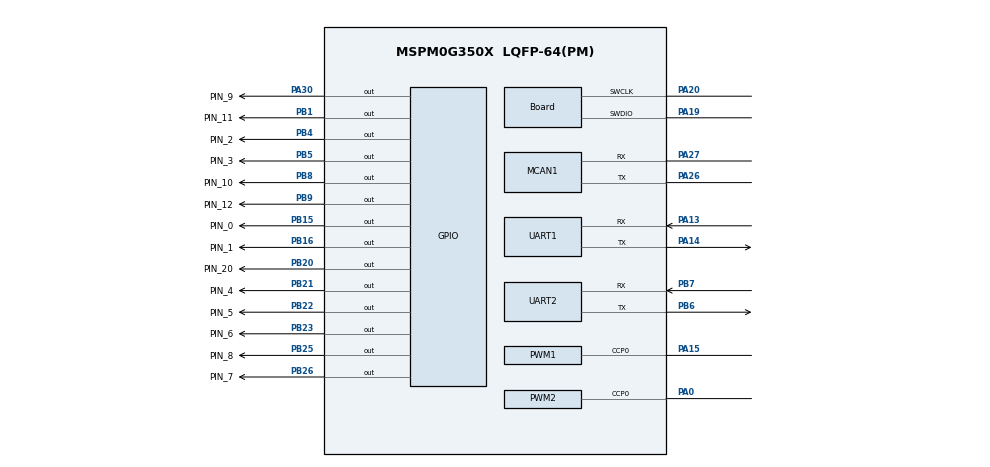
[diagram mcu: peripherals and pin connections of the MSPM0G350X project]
/**
 * @cliArgs --device "MSPM0G350X" --package "LQFP-64(PM)" --part "Default" --product "mspm0_sdk@2.00.01.00"
 * @versions {"tool":"1.20.0+3587"}
 */

/**
 * Import the modules used in this configuration.
 */
const GPIO   = scripting.addModule("/ti/driverlib/GPIO", {}, false);
const GPIO1  = GPIO.addInstance();
const GPIO2  = GPIO.addInstance();
const GPIO3  = GPIO.addInstance();
const GPIO4  = GPIO.addInstance();
const GPIO5  = GPIO.addInstance();
const GPIO6  = GPIO.addInstance();
const GPIO7  = GPIO.addInstance();
const GPIO8  = GPIO.addInstance();
const GPIO9  = GPIO.addInstance();
const GPIO10 = GPIO.addInstance();
const GPIO11 = GPIO.addInstance();
const GPIO12 = GPIO.addInstance();
const GPIO13 = GPIO.addInstance();
const GPIO14 = GPIO.addInstance();
const MCAN   = scripting.addModule("/ti/driverlib/MCAN", {}, false);
const MCAN1  = MCAN.addInstance();
const PWM    = scripting.addModule("/ti/driverlib/PWM", {}, false);
const PWM1   = PWM.addInstance();
const PWM2   = PWM.addInstance();
const SYSCTL = scripting.addModule("/ti/driverlib/SYSCTL");
const TIMER  = scripting.addModule("/ti/driverlib/TIMER", {}, false);
const TIMER1 = TIMER.addInstance();
const TIMER2 = TIMER.addInstance();
const TIMER3 = TIMER.addInstance();
const UART   = scripting.addModule("/ti/driverlib/UART", {}, false);
const UART1  = UART.addInstance();
const UART2  = UART.addInstance();
const WWDT   = scripting.addModule("/ti/driverlib/WWDT", {}, false);
const WWDT1  = WWDT.addInstance();

/**
 * Write custom configuration values to the imported modules.
 */
const divider5       = system.clockTree["PLL_CLK1_DIV"];
divider5.divideValue = 8;

const divider9       = system.clockTree["UDIV"];
divider9.divideValue = 2;

const multiplier2         = system.clockTree["PLL_QDIV"];
multiplier2.multiplyValue = 5;

const mux2       = system.clockTree["CANCLKMUX"];
mux2.inputSelect = "CANCLKMUX_PLLCLK1_OUT";

const mux8       = system.clockTree["HSCLKMUX"];
mux8.inputSelect = "HSCLKMUX_SYSPLL0";

const pinFunction4     = system.clockTree["HFXT"];
pinFunction4.inputFreq = 16;
pinFunction4.enable    = true;

GPIO1.$name                          = "ZCRESET1";
GPIO1.associatedPins[0].$name        = "PIN_0";
GPIO1.associatedPins[0].initialValue = "SET";
GPIO1.associatedPins[0].ioStructure  = "SD";
GPIO1.associatedPins[0].pin.$assign  = "PB15";

const Board                       = scripting.addModule("/ti/driverlib/Board", {}, false);
Board.peripheral.$assign          = "DEBUGSS";
Board.peripheral.swclkPin.$assign = "PA20";
Board.peripheral.swdioPin.$assign = "PA19";

GPIO2.$name                          = "ZTXEN1";
GPIO2.associatedPins[0].$name        = "PIN_1";
GPIO2.associatedPins[0].initialValue = "SET";
GPIO2.associatedPins[0].ioStructure  = "SD";
GPIO2.associatedPins[0].pin.$assign  = "PB16";

GPIO3.$name                          = "ZCRESET2";
GPIO3.associatedPins[0].$name        = "PIN_2";
GPIO3.associatedPins[0].initialValue = "SET";
GPIO3.associatedPins[0].ioStructure  = "SD";
GPIO3.associatedPins[0].pin.$assign  = "PB4";

GPIO4.$name                          = "ZTXEN2";
GPIO4.associatedPins[0].$name        = "PIN_3";
GPIO4.associatedPins[0].initialValue = "SET";
GPIO4.associatedPins[0].ioStructure  = "SD";
GPIO4.associatedPins[0].pin.$assign  = "PB5";

GPIO5.$name                         = "ROUT_Y0";
GPIO5.associatedPins[0].$name       = "PIN_20";
GPIO5.associatedPins[0].ioStructure = "SD";
GPIO5.associatedPins[0].pin.$assign = "PB20";

GPIO6.$name                         = "ROUT_Y1";
GPIO6.associatedPins[0].$name       = "PIN_4";
GPIO6.associatedPins[0].ioStructure = "SD";
GPIO6.associatedPins[0].pin.$assign = "PB21";

GPIO7.$name                         = "ROUT_Y2";
GPIO7.associatedPins[0].$name       = "PIN_5";
GPIO7.associatedPins[0].ioStructure = "SD";
GPIO7.associatedPins[0].pin.$assign = "PB22";

GPIO8.$name                         = "ROUT_Y3";
GPIO8.associatedPins[0].$name       = "PIN_6";
GPIO8.associatedPins[0].ioStructure = "SD";
GPIO8.associatedPins[0].pin.$assign = "PB23";

GPIO9.$name                         = "ROUT_Y6";
GPIO9.associatedPins[0].$name       = "PIN_7";
GPIO9.associatedPins[0].ioStructure = "SD";
GPIO9.associatedPins[0].pin.$assign = "PB26";

GPIO10.$name                         = "ROUT_Y5";
GPIO10.associatedPins[0].$name       = "PIN_8";
GPIO10.associatedPins[0].ioStructure = "SD";
GPIO10.associatedPins[0].pin.$assign = "PB25";

GPIO11.$name                         = "PWR_FSEN";
GPIO11.associatedPins[0].$name       = "PIN_9";
GPIO11.associatedPins[0].ioStructure = "SD";
GPIO11.associatedPins[0].pin.$assign = "PA30";

GPIO12.$name                         = "m485BTE";
GPIO12.associatedPins[0].$name       = "PIN_10";
GPIO12.associatedPins[0].ioStructure = "SD";
GPIO12.associatedPins[0].pin.$assign = "PB8";

GPIO13.$name                         = "LED_485B";
GPIO13.associatedPins[0].$name       = "PIN_11";
GPIO13.associatedPins[0].ioStructure = "SD";
GPIO13.associatedPins[0].pin.$assign = "PB1";

GPIO14.$name                         = "LED_MCU";
GPIO14.associatedPins[0].ioStructure = "SD";
GPIO14.associatedPins[0].$name       = "PIN_12";
GPIO14.associatedPins[0].pin.$assign = "PB9";

MCAN1.$name                    = "MCAN0";
MCAN1.fdMode                   = false;
MCAN1.emulationEnable          = true;
MCAN1.autoWkupEnable           = true;
MCAN1.wkupReqEnable            = true;
MCAN1.desiredNomRate           = 100;
MCAN1.desiredDataRate          = 0.1;
MCAN1.enableInterrupt          = true;
MCAN1.interruptFlags           = ["DL_MCAN_INTERRUPT_DRX","DL_MCAN_INTERRUPT_RF0F","DL_MCAN_INTERRUPT_RF0L","DL_MCAN_INTERRUPT_RF0N","DL_MCAN_INTERRUPT_RF0W","DL_MCAN_INTERRUPT_RF1F","DL_MCAN_INTERRUPT_RF1L","DL_MCAN_INTERRUPT_RF1N","DL_MCAN_INTERRUPT_RF1W"];
MCAN1.interruptLine1Flag       = ["DL_MCAN_INTR_MASK_ALL"];
MCAN1.interruptLine            = ["DL_MCAN_INTR_LINE_NUM_1"];
MCAN1.m0interrupts             = ["DL_MCAN_MSP_INTERRUPT_LINE1"];
MCAN1.peripheral.rxPin.$assign = "PA27";
MCAN1.peripheral.txPin.$assign = "PA26";
MCAN1.txPinConfig.$name        = "ti_driverlib_gpio_GPIOPinGeneric4";
MCAN1.rxPinConfig.$name        = "ti_driverlib_gpio_GPIOPinGeneric5";

PWM1.ccIndexCmpl                             = [0,1];
PWM1.$name                                   = "ZCLK1";
PWM1.pwmMode                                 = "CENTER_ALIGN";
PWM1.ccIndex                                 = [0];
PWM1.dutyArgs                                = "[50,0,0,0]";
PWM1.clockDivider                            = 8;
PWM1.timerCount                              = 80;
PWM1.peripheral.$assign                      = "TIMA1";
PWM1.peripheral.ccp0Pin.$assign              = "PA15";
PWM1.peripheral.ccp0Pin_cmpl.$assign         = "PB24";
PWM1.PWM_CHANNEL_0.$name                     = "ti_driverlib_pwm_PWMTimerCC0";
PWM1.ccp0PinConfig.direction                 = scripting.forceWrite("OUTPUT");
PWM1.ccp0PinConfig.hideOutputInversion       = scripting.forceWrite(false);
PWM1.ccp0PinConfig.onlyInternalResistor      = scripting.forceWrite(false);
PWM1.ccp0PinConfig.passedPeripheralType      = scripting.forceWrite("Digital");
PWM1.ccp0PinConfig.$name                     = "ti_driverlib_gpio_GPIOPinGeneric0";
PWM1.ccp0Pin_cmplConfig.direction            = scripting.forceWrite("OUTPUT");
PWM1.ccp0Pin_cmplConfig.hideOutputInversion  = scripting.forceWrite(false);
PWM1.ccp0Pin_cmplConfig.onlyInternalResistor = scripting.forceWrite(false);
PWM1.ccp0Pin_cmplConfig.passedPeripheralType = scripting.forceWrite("Digital");
PWM1.ccp0Pin_cmplConfig.$name                = "ti_driverlib_gpio_GPIOPinGeneric2";

PWM2.ccIndexCmpl                             = [0,1];
PWM2.pwmMode                                 = "CENTER_ALIGN";
PWM2.ccIndex                                 = [0];
PWM2.dutyArgs                                = "[50,0,0,0]";
PWM2.$name                                   = "ZCLK2";
PWM2.clockDivider                            = 8;
PWM2.timerCount                              = 80;
PWM2.peripheral.$assign                      = "TIMA0";
PWM2.peripheral.ccp0Pin.$assign              = "PA0";
PWM2.peripheral.ccp0Pin_cmpl.$assign         = "PA22";
PWM2.PWM_CHANNEL_0.$name                     = "ti_driverlib_pwm_PWMTimerCC0_COPY";
PWM2.ccp0PinConfig.direction                 = scripting.forceWrite("OUTPUT");
PWM2.ccp0PinConfig.hideOutputInversion       = scripting.forceWrite(false);
PWM2.ccp0PinConfig.onlyInternalResistor      = scripting.forceWrite(false);
PWM2.ccp0PinConfig.passedPeripheralType      = scripting.forceWrite("Digital");
PWM2.ccp0PinConfig.$name                     = "ti_driverlib_gpio_GPIOPinGeneric0_COPY";
PWM2.ccp0Pin_cmplConfig.direction            = scripting.forceWrite("OUTPUT");
PWM2.ccp0Pin_cmplConfig.hideOutputInversion  = scripting.forceWrite(false);
PWM2.ccp0Pin_cmplConfig.onlyInternalResistor = scripting.forceWrite(false);
PWM2.ccp0Pin_cmplConfig.passedPeripheralType = scripting.forceWrite("Digital");
PWM2.ccp0Pin_cmplConfig.$name                = "ti_driverlib_gpio_GPIOPinGeneric2_COPY";

SYSCTL.forceDefaultClkConfig = true;
SYSCTL.clockTreeEn           = true;

TIMER1.$name              = "scl1_time";
TIMER1.timerPeriod        = "0.1 ms";
TIMER1.timerClkDiv        = 4;
TIMER1.interrupts         = ["ZERO"];
TIMER1.peripheral.$assign = "TIMG0";

TIMER2.$name              = "scl1_com_idle";
TIMER2.timerClkDiv        = 4;
TIMER2.interrupts         = ["ZERO"];
TIMER2.timerPeriod        = "0.02 ms";
TIMER2.peripheral.$assign = "TIMG6";

TIMER3.timerClkDiv        = 4;
TIMER3.interrupts         = ["ZERO"];
TIMER3.$name              = "scl2_com_idle";
TIMER3.timerPeriod        = "0.1 ms";
TIMER3.peripheral.$assign = "TIMG7";

UART1.targetBaudRate                    = 125000;
UART1.parity                            = "EVEN";
UART1.enabledDMATXTriggers              = "DL_UART_DMA_INTERRUPT_TX";
UART1.$name                             = "ZSCL1";
UART1.txFifoThreshold                   = "DL_UART_TX_FIFO_LEVEL_ONE_ENTRY";
UART1.rxFifoThreshold                   = "DL_UART_RX_FIFO_LEVEL_ONE_ENTRY";
UART1.enabledInterrupts                 = ["EOT_DONE","RX","RX_TIMEOUT_ERROR","TX"];
UART1.interruptPriority                 = "0";
UART1.peripheral.$assign                = "UART3";
UART1.peripheral.rxPin.$assign          = "PA13";
UART1.peripheral.txPin.$assign          = "PA14";
UART1.txPinConfig.direction             = scripting.forceWrite("OUTPUT");
UART1.txPinConfig.hideOutputInversion   = scripting.forceWrite(false);
UART1.txPinConfig.onlyInternalResistor  = scripting.forceWrite(false);
UART1.txPinConfig.passedPeripheralType  = scripting.forceWrite("Digital");
UART1.txPinConfig.$name                 = "ti_driverlib_gpio_GPIOPinGeneric1";
UART1.rxPinConfig.hideOutputInversion   = scripting.forceWrite(false);
UART1.rxPinConfig.onlyInternalResistor  = scripting.forceWrite(false);
UART1.rxPinConfig.passedPeripheralType  = scripting.forceWrite("Digital");
UART1.rxPinConfig.$name                 = "ti_driverlib_gpio_GPIOPinGeneric3";
UART1.DMA_CHANNEL_TX.srcLength          = "BYTE";
UART1.DMA_CHANNEL_TX.dstLength          = "BYTE";
UART1.DMA_CHANNEL_TX.addressMode        = "b2f";
UART1.DMA_CHANNEL_TX.$name              = "DMA_SCL1_TX";
UART1.DMA_CHANNEL_TX.peripheral.$assign = "DMA_CH0";

UART2.parity                            = "EVEN";
UART2.enabledDMATXTriggers              = "DL_UART_DMA_INTERRUPT_TX";
UART2.$name                             = "ZSCL2";
UART2.enableDMARX                       = false;
UART2.txFifoThreshold                   = "DL_UART_TX_FIFO_LEVEL_EMPTY";
UART2.rxFifoThreshold                   = "DL_UART_RX_FIFO_LEVEL_3_4_FULL";
UART2.targetBaudRate                    = 115200;
UART2.enabledInterrupts                 = ["EOT_DONE","RX","RX_TIMEOUT_ERROR","TX"];
UART2.peripheral.$assign                = "UART1";
UART2.peripheral.rxPin.$assign          = "PB7";
UART2.peripheral.txPin.$assign          = "PB6";
UART2.txPinConfig.direction             = scripting.forceWrite("OUTPUT");
UART2.txPinConfig.hideOutputInversion   = scripting.forceWrite(false);
UART2.txPinConfig.onlyInternalResistor  = scripting.forceWrite(false);
UART2.txPinConfig.passedPeripheralType  = scripting.forceWrite("Digital");
UART2.txPinConfig.$name                 = "ti_driverlib_gpio_GPIOPinGeneric1_COPY";
UART2.rxPinConfig.hideOutputInversion   = scripting.forceWrite(false);
UART2.rxPinConfig.onlyInternalResistor  = scripting.forceWrite(false);
UART2.rxPinConfig.passedPeripheralType  = scripting.forceWrite("Digital");
UART2.rxPinConfig.$name                 = "ti_driverlib_gpio_GPIOPinGeneric3_COPY";
UART2.DMA_CHANNEL_TX.srcLength          = "BYTE";
UART2.DMA_CHANNEL_TX.dstLength          = "BYTE";
UART2.DMA_CHANNEL_TX.addressMode        = "b2f";
UART2.DMA_CHANNEL_TX.$name              = "DMA_SCL2_TX";
UART2.DMA_CHANNEL_TX.peripheral.$assign = "DMA_CH1";

WWDT1.$name     = "WWDT0";
WWDT1.sleepMode = true;
WWDT1.profile   = "CONFIG_PROFILE_2";

/**
 * Pinmux solution for unlocked pins/peripherals. This ensures that minor changes to the automatic solver in a future
 * version of the tool will not impact the pinmux you originally saw.  These lines can be completely deleted in order to
 * re-solve from scratch.
 */
pinFunction4.peripheral.$suggestSolution           = "SYSCTL";
pinFunction4.peripheral.hfxInPin.$suggestSolution  = "PA5";
pinFunction4.peripheral.hfxOutPin.$suggestSolution = "PA6";
MCAN1.peripheral.$suggestSolution                  = "CANFD0";
WWDT1.peripheral.$suggestSolution                  = "WWDT0";
